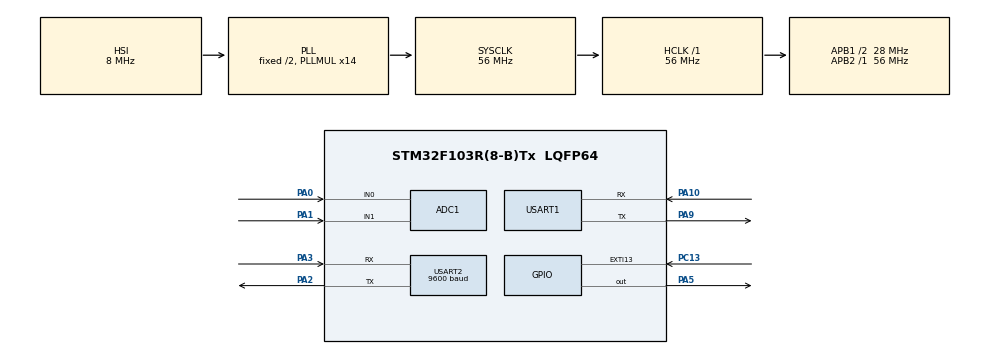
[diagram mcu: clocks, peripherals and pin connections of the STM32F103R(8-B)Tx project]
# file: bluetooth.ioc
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ADC1.Channel-25\#ChannelRegularConversion=ADC_CHANNEL_0
ADC1.Channel-26\#ChannelRegularConversion=ADC_CHANNEL_1
ADC1.ContinuousConvMode=DISABLE
ADC1.DataAlign=ADC_DATAALIGN_RIGHT
ADC1.DiscontinuousConvMode=DISABLE
ADC1.EnableRegularConversion=ENABLE
ADC1.InjNumberOfConversion=0
ADC1.NbrOfConversion=2
ADC1.NbrOfConversionFlag=1
ADC1.Rank-25\#ChannelRegularConversion=1
ADC1.Rank-26\#ChannelRegularConversion=2
ADC1.SamplingTime-25\#ChannelRegularConversion=ADC_SAMPLETIME_1CYCLE_5
ADC1.SamplingTime-26\#ChannelRegularConversion=ADC_SAMPLETIME_55CYCLES_5
ADC1.ScanConvMode=ADC_SCAN_ENABLE
ADC1.master=1
Dma.ADC1.1.Direction=DMA_PERIPH_TO_MEMORY
Dma.ADC1.1.Instance=DMA1_Channel1
Dma.ADC1.1.MemDataAlignment=DMA_MDATAALIGN_WORD
Dma.ADC1.1.MemInc=DMA_MINC_ENABLE
Dma.ADC1.1.Mode=DMA_CIRCULAR
Dma.ADC1.1.PeriphDataAlignment=DMA_PDATAALIGN_WORD
Dma.ADC1.1.PeriphInc=DMA_PINC_DISABLE
Dma.ADC1.1.Priority=DMA_PRIORITY_LOW
Dma.Request0=USART1_TX
Dma.Request1=ADC1
Dma.USART1_TX.0.Direction=DMA_MEMORY_TO_PERIPH
Dma.USART1_TX.0.Instance=DMA1_Channel4
Dma.USART1_TX.0.MemDataAlignment=DMA_MDATAALIGN_BYTE
Dma.USART1_TX.0.MemInc=DMA_MINC_ENABLE
Dma.USART1_TX.0.Mode=DMA_CIRCULAR
Dma.USART1_TX.0.PeriphDataAlignment=DMA_PDATAALIGN_BYTE
Dma.USART1_TX.0.PeriphInc=DMA_PINC_DISABLE
Dma.USART1_TX.0.Priority=DMA_PRIORITY_LOW
Mcu.Family=STM32F1
Mcu.Name=STM32F103R(8-B)Tx
Mcu.Package=LQFP64
NVIC.DMA1_Channel1_IRQn=true\:0\:0\:false\:false\:true
NVIC.DMA1_Channel4_IRQn=true\:0\:0\:false\:false\:true
NVIC.EXTI15_10_IRQn=true\:0\:0\:false\:false\:true
NVIC.PriorityGroup=NVIC_PRIORITYGROUP_4
PA0-WKUP.Signal=ADCx_IN0
PA1.Signal=ADCx_IN1
PA10.Mode=Asynchronous
PA10.Signal=USART1_RX
PA13.Mode=Serial_Wire
PA13.Signal=SYS_JTMS-SWDIO
PA14.Mode=Serial_Wire
PA14.Signal=SYS_JTCK-SWCLK
PA2.Mode=Asynchronous
PA2.Signal=USART2_TX
PA3.GPIO_Mode=GPIO_MODE_INPUT
PA3.GPIO_PuPd=GPIO_NOPULL
PA3.GPIO_Speed=GPIO_SPEED_FREQ_LOW
PA3.Mode=Asynchronous
PA3.Signal=USART2_RX
PA5.GPIO_ModeDefaultOutputPP=GPIO_MODE_OUTPUT_PP
PA5.GPIO_PuPd=GPIO_NOPULL
PA5.GPIO_Speed=GPIO_SPEED_FREQ_LOW
PA5.PinState=GPIO_PIN_RESET
PA5.Signal=GPIO_Output
PA9.Mode=Asynchronous
PA9.Signal=USART1_TX
PB3.Signal=SYS_JTDO-TRACESWO
PC13-TAMPER-RTC.GPIO_ModeDefaultEXTI=GPIO_MODE_IT_RISING
PC13-TAMPER-RTC.GPIO_PuPd=GPIO_NOPULL
PC13-TAMPER-RTC.Signal=GPXTI13
PC14-OSC32_IN.Signal=RCC_OSC32_IN
PC15-OSC32_OUT.Signal=RCC_OSC32_OUT
PD0-OSC_IN.Signal=RCC_OSC_IN
PD1-OSC_OUT.Signal=RCC_OSC_OUT
ProjectManager.HeapSize=0x200
ProjectManager.StackSize=0x400
ProjectManager.TargetToolchain=TrueSTUDIO
RCC.ADCPresc=RCC_ADCPCLK2_DIV4
RCC.AHBFreq_Value=56000000
RCC.APB1CLKDivider=RCC_HCLK_DIV2
RCC.APB1Freq_Value=28000000
RCC.APB1TimFreq_Value=56000000
RCC.APB2Freq_Value=56000000
RCC.APB2TimFreq_Value=56000000
RCC.HCLKFreq_Value=56000000
RCC.PLLMUL=RCC_PLL_MUL14
RCC.SYSCLKFreq_VALUE=56000000
RCC.SYSCLKSource=RCC_SYSCLKSOURCE_PLLCLK
RCC.USBFreq_Value=56000000
SH.ADCx_IN0.0=ADC1_IN0,IN0
SH.ADCx_IN1.0=ADC1_IN1,IN1
USART1.VirtualMode=VM_ASYNC
USART2.BaudRate=9600
USART2.VirtualMode=VM_ASYNC
board=NUCLEO-F103RB

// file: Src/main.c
/**
  ******************************************************************************
  * File Name          : main.c
  * Description        : Main program body
  ******************************************************************************
  ** This notice applies to any and all portions of this file
  * that are not between comment pairs USER CODE BEGIN and
  * USER CODE END. Other portions of this file, whether
  * inserted by the user or by software development tools
  * are owned by their respective copyright owners.
  *
  * COPYRIGHT(c) 2017 STMicroelectronics
  *
  * Redistribution and use in source and binary forms, with or without modification,
  * are permitted provided that the following conditions are met:
  *   1. Redistributions of source code must retain the above copyright notice,
  *      this list of conditions and the following disclaimer.
  *   2. Redistributions in binary form must reproduce the above copyright notice,
  *      this list of conditions and the following disclaimer in the documentation
  *      and/or other materials provided with the distribution.
  *   3. Neither the name of STMicroelectronics nor the names of its contributors
  *      may be used to endorse or promote products derived from this software
  *      without specific prior written permission.
  *
  * THIS SOFTWARE IS PROVIDED BY THE COPYRIGHT HOLDERS AND CONTRIBUTORS "AS IS"
  * AND ANY EXPRESS OR IMPLIED WARRANTIES, INCLUDING, BUT NOT LIMITED TO, THE
  * IMPLIED WARRANTIES OF MERCHANTABILITY AND FITNESS FOR A PARTICULAR PURPOSE ARE
  * DISCLAIMED. IN NO EVENT SHALL THE COPYRIGHT HOLDER OR CONTRIBUTORS BE LIABLE
  * FOR ANY DIRECT, INDIRECT, INCIDENTAL, SPECIAL, EXEMPLARY, OR CONSEQUENTIAL
  * DAMAGES (INCLUDING, BUT NOT LIMITED TO, PROCUREMENT OF SUBSTITUTE GOODS OR
  * SERVICES; LOSS OF USE, DATA, OR PROFITS; OR BUSINESS INTERRUPTION) HOWEVER
  * CAUSED AND ON ANY THEORY OF LIABILITY, WHETHER IN CONTRACT, STRICT LIABILITY,
  * OR TORT (INCLUDING NEGLIGENCE OR OTHERWISE) ARISING IN ANY WAY OUT OF THE USE
  * OF THIS SOFTWARE, EVEN IF ADVISED OF THE POSSIBILITY OF SUCH DAMAGE.
  *
  ******************************************************************************
  */
#include "main.h"
#include "stm32f1xx_hal.h"
#define LEN 9

ADC_HandleTypeDef hadc1;
DMA_HandleTypeDef hdma_adc1;

UART_HandleTypeDef huart1;
UART_HandleTypeDef huart2;
DMA_HandleTypeDef hdma_usart1_tx;

/* USER CODE BEGIN PV */
/* Private variables ---------------------------------------------------------*/

/* USER CODE END PV */

void SystemClock_Config(void);
static void MX_GPIO_Init(void);
static void MX_DMA_Init(void);
static void MX_USART2_UART_Init(void);
static void MX_USART1_UART_Init(void);
static void MX_ADC1_Init(void);

/* USER CODE BEGIN PFP */
/* Private function prototypes -----------------------------------------------*/

/* USER CODE END PFP */

/* USER CODE BEGIN 0 */
__IO uint32_t ADCvalue[2];
u_int8_t RcvData[32];
u_int8_t* currentline;
float data[2];

/* USER CODE END 0 */
float floatmap(float x, float inMin, float inMax, float outMin, float outMax)
{
  return (x-inMin)*(outMax-outMin)/(inMax-inMin)+outMin;
}

void HAL_ADC_ConvCpltCallback(ADC_HandleTypeDef* hadc)
{
	/* USER CODE END WHILE */
	data[0] = floatmap(ADCvalue[0], 0, 4095, 0, 3.3);
	sprintf(currentline, "s%f", data[0]);
	HAL_UART_Transmit_DMA(&huart1, currentline, LEN);

	data[1] = floatmap(ADCvalue[1], 0, 4095, 0, 3.3);
	sprintf(currentline, "e%f", data[1]);
	HAL_UART_Transmit_DMA(&huart1, currentline, LEN);

}

int main(void)
{
	currentline = RcvData;

  /* MCU Configuration----------------------------------------------------------*/

  /* Reset of all peripherals, Initializes the Flash interface and the Systick. */
  HAL_Init();

  /* Configure the system clock */
  SystemClock_Config();

  /* Initialize all configured peripherals */
  MX_GPIO_Init();
  MX_DMA_Init();
  MX_USART2_UART_Init();
  MX_USART1_UART_Init();
  MX_ADC1_Init();

  HAL_ADCEx_Calibration_Start(&hadc1);

  /* Infinite loop */
  /* USER CODE BEGIN WHILE */
  while (1)
  {
	  HAL_ADC_Start_DMA(&hadc1, ADCvalue, 2);

  }

}

/** System Clock Configuration
*/
void SystemClock_Config(void)
{

  RCC_OscInitTypeDef RCC_OscInitStruct;
  RCC_ClkInitTypeDef RCC_ClkInitStruct;
  RCC_PeriphCLKInitTypeDef PeriphClkInit;

    /**Initializes the CPU, AHB and APB busses clocks
    */
  RCC_OscInitStruct.OscillatorType = RCC_OSCILLATORTYPE_HSI;
  RCC_OscInitStruct.HSIState = RCC_HSI_ON;
  RCC_OscInitStruct.HSICalibrationValue = 16;
  RCC_OscInitStruct.PLL.PLLState = RCC_PLL_ON;
  RCC_OscInitStruct.PLL.PLLSource = RCC_PLLSOURCE_HSI_DIV2;
  RCC_OscInitStruct.PLL.PLLMUL = RCC_PLL_MUL14;
  if (HAL_RCC_OscConfig(&RCC_OscInitStruct) != HAL_OK)
  {
    _Error_Handler(__FILE__, __LINE__);
  }

    /**Initializes the CPU, AHB and APB busses clocks
    */
  RCC_ClkInitStruct.ClockType = RCC_CLOCKTYPE_HCLK|RCC_CLOCKTYPE_SYSCLK
                              |RCC_CLOCKTYPE_PCLK1|RCC_CLOCKTYPE_PCLK2;
  RCC_ClkInitStruct.SYSCLKSource = RCC_SYSCLKSOURCE_PLLCLK;
  RCC_ClkInitStruct.AHBCLKDivider = RCC_SYSCLK_DIV1;
  RCC_ClkInitStruct.APB1CLKDivider = RCC_HCLK_DIV2;
  RCC_ClkInitStruct.APB2CLKDivider = RCC_HCLK_DIV1;

  if (HAL_RCC_ClockConfig(&RCC_ClkInitStruct, FLASH_LATENCY_2) != HAL_OK)
  {
    _Error_Handler(__FILE__, __LINE__);
  }

  PeriphClkInit.PeriphClockSelection = RCC_PERIPHCLK_ADC;
  PeriphClkInit.AdcClockSelection = RCC_ADCPCLK2_DIV4;
  if (HAL_RCCEx_PeriphCLKConfig(&PeriphClkInit) != HAL_OK)
  {
    _Error_Handler(__FILE__, __LINE__);
  }

    /**Configure the Systick interrupt time
    */
  HAL_SYSTICK_Config(HAL_RCC_GetHCLKFreq()/1000);

    /**Configure the Systick
    */
  HAL_SYSTICK_CLKSourceConfig(SYSTICK_CLKSOURCE_HCLK);

  /* SysTick_IRQn interrupt configuration */
  HAL_NVIC_SetPriority(SysTick_IRQn, 0, 0);
}

/* ADC1 init function */
static void MX_ADC1_Init(void)
{

  ADC_ChannelConfTypeDef sConfig;

    /**Common config
    */
  hadc1.Instance = ADC1;
  hadc1.Init.ScanConvMode = ADC_SCAN_ENABLE;
  hadc1.Init.ContinuousConvMode = DISABLE;
  hadc1.Init.DiscontinuousConvMode = DISABLE;
  hadc1.Init.ExternalTrigConv = ADC_SOFTWARE_START;
  hadc1.Init.DataAlign = ADC_DATAALIGN_RIGHT;
  hadc1.Init.NbrOfConversion = 2;
  if (HAL_ADC_Init(&hadc1) != HAL_OK)
  {
    _Error_Handler(__FILE__, __LINE__);
  }

    /**Configure Regular Channel
    */
  sConfig.Channel = ADC_CHANNEL_0;
  sConfig.Rank = 1;
  sConfig.SamplingTime = ADC_SAMPLETIME_1CYCLE_5;
  if (HAL_ADC_ConfigChannel(&hadc1, &sConfig) != HAL_OK)
  {
    _Error_Handler(__FILE__, __LINE__);
  }

    /**Configure Regular Channel
    */
  sConfig.Channel = ADC_CHANNEL_1;
  sConfig.Rank = 2;
  sConfig.SamplingTime = ADC_SAMPLETIME_55CYCLES_5;
  if (HAL_ADC_ConfigChannel(&hadc1, &sConfig) != HAL_OK)
  {
    _Error_Handler(__FILE__, __LINE__);
  }

}

/* USART1 init function */
static void MX_USART1_UART_Init(void)
{

  huart1.Instance = USART1;
  huart1.Init.BaudRate = 115200;
  huart1.Init.WordLength = UART_WORDLENGTH_8B;
  huart1.Init.StopBits = UART_STOPBITS_1;
  huart1.Init.Parity = UART_PARITY_NONE;
  huart1.Init.Mode = UART_MODE_TX_RX;
  huart1.Init.HwFlowCtl = UART_HWCONTROL_NONE;
  huart1.Init.OverSampling = UART_OVERSAMPLING_16;
  if (HAL_UART_Init(&huart1) != HAL_OK)
  {
    _Error_Handler(__FILE__, __LINE__);
  }

}

/* USART2 init function */
static void MX_USART2_UART_Init(void)
{

  huart2.Instance = USART2;
  huart2.Init.BaudRate = 115200;
  huart2.Init.WordLength = UART_WORDLENGTH_8B;
  huart2.Init.StopBits = UART_STOPBITS_1;
  huart2.Init.Parity = UART_PARITY_NONE;
  huart2.Init.Mode = UART_MODE_TX_RX;
  huart2.Init.HwFlowCtl = UART_HWCONTROL_NONE;
  huart2.Init.OverSampling = UART_OVERSAMPLING_16;
  if (HAL_UART_Init(&huart2) != HAL_OK)
  {
    _Error_Handler(__FILE__, __LINE__);
  }

}

static void MX_DMA_Init(void)
{
  /* DMA controller clock enable */
  __HAL_RCC_DMA1_CLK_ENABLE();

  /* DMA interrupt init */
  /* DMA1_Channel1_IRQn interrupt configuration */
  HAL_NVIC_SetPriority(DMA1_Channel1_IRQn, 0, 0);
  HAL_NVIC_EnableIRQ(DMA1_Channel1_IRQn);
  /* DMA1_Channel4_IRQn interrupt configuration */
  HAL_NVIC_SetPriority(DMA1_Channel4_IRQn, 0, 0);
  HAL_NVIC_EnableIRQ(DMA1_Channel4_IRQn);

}

/** Configure pins as
        * Analog
        * Input
        * Output
        * EVENT_OUT
        * EXTI
*/
static void MX_GPIO_Init(void)
{

  GPIO_InitTypeDef GPIO_InitStruct;

  /* GPIO Ports Clock Enable */
  __HAL_RCC_GPIOC_CLK_ENABLE();
  __HAL_RCC_GPIOD_CLK_ENABLE();
  __HAL_RCC_GPIOA_CLK_ENABLE();
  __HAL_RCC_GPIOB_CLK_ENABLE();

  /*Configure GPIO pin Output Level */
  HAL_GPIO_WritePin(GPIOA, GPIO_PIN_5, GPIO_PIN_RESET);

  /*Configure GPIO pin : PC13 */
  GPIO_InitStruct.Pin = GPIO_PIN_13;
  GPIO_InitStruct.Mode = GPIO_MODE_IT_RISING;
  GPIO_InitStruct.Pull = GPIO_NOPULL;
  HAL_GPIO_Init(GPIOC, &GPIO_InitStruct);

  /*Configure GPIO pin : PA5 */
  GPIO_InitStruct.Pin = GPIO_PIN_5;
  GPIO_InitStruct.Mode = GPIO_MODE_OUTPUT_PP;
  GPIO_InitStruct.Speed = GPIO_SPEED_FREQ_LOW;
  HAL_GPIO_Init(GPIOA, &GPIO_InitStruct);

  /* EXTI interrupt init*/
  HAL_NVIC_SetPriority(EXTI15_10_IRQn, 0, 0);
  HAL_NVIC_EnableIRQ(EXTI15_10_IRQn);

}

void _Error_Handler(char * file, int line)
{
  while(1)
  {
  }
}

/************************ (C) COPYRIGHT STMicroelectronics *****END OF FILE****/
